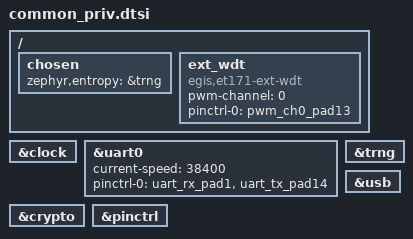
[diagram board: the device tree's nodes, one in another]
#include "clock.dtsi"
#include "crypto.dtsi"
#include "pinctrl.dtsi"
#include "power.dtsi"
#include "trng.dtsi"
#include "usb.dtsi"

#include <egis/egis_et171_pinctrl.dtsi>

/delete-node/ &clk_mtimer;

/ {
	chosen {
		zephyr,entropy = &trng;
	};

	ext_wdt: ext_wdt {
		compatible = "egis,et171-ext-wdt";
		status = "okay";
		pwm-channel = <0>;
		pinctrl-0 = <&pwm_ch0_pad13>;
		pinctrl-names = "default";
	};
};

&clock {
	status = "okay";
};

&uart0 {
	status = "okay";
	current-speed = <38400>;
	pinctrl-0 = <&uart_rx_pad1 &uart_tx_pad14>;
	pinctrl-names = "default";
};

&trng {
	status = "okay";
};

&crypto {
	status = "okay";
};

&pinctrl {
	status = "okay";
};

zephyr_udc0: &usb {
	status = "okay";
};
